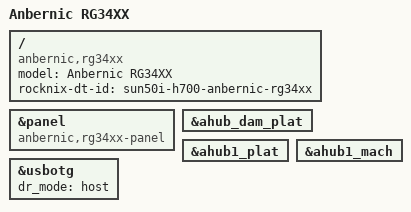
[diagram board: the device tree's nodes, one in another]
// SPDX-License-Identifier: (GPL-2.0-only OR BSD-2-Clause)
/*
 * Copyright (C) 2024 Ryan Walklin <ryan@testtoast.com>.
 * Copyright (C) 2024 Chris Morgan <macroalpha82@gmail.com>.
 */

#include "sun50i-h700-anbernic-rg35xx-plus.dts"

/ {
	model = "Anbernic RG34XX";
	compatible = "anbernic,rg34xx", "allwinner,sun50i-h700";
	rocknix-dt-id = "sun50i-h700-anbernic-rg34xx";
};

&panel {
	compatible = "anbernic,rg34xx-panel", "panel-mipi-dpi-spi";
};

/* Enable HDMI audio via Allwinner AHUB → dw-hdmi-i2s-audio. */
&ahub_dam_plat {
	status = "okay";
};

&ahub1_plat {
	status = "okay";
};

&ahub1_mach {
	status = "okay";
};

/* USB-C host mode: force host so MUSB enables VBUS without CC-pin ID detection */
&usbotg {
	dr_mode = "host";
};
